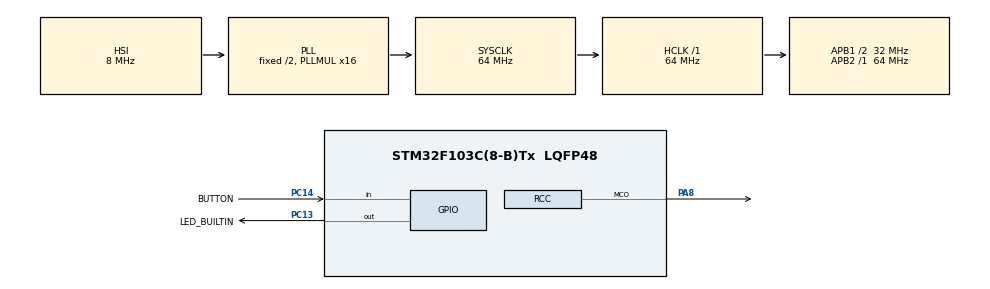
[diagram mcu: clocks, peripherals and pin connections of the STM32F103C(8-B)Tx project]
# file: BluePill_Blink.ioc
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Mcu.Family=STM32F1
PC13-TAMPER-RTC.Signal=GPIO_Output
RCC.APB1CLKDivider=RCC_HCLK_DIV2
PC14-OSC32_IN.Signal=GPIO_Input
RCC.SYSCLKSource=RCC_SYSCLKSOURCE_PLLCLK
ProjectManager.StackSize=0x400
PA13.Signal=SYS_JTMS-SWDIO
ProjectManager.TargetToolchain=STM32CubeIDE
RCC.HCLKFreq_Value=64000000
RCC.APB2TimFreq_Value=64000000
RCC.USBFreq_Value=64000000
RCC.AHBFreq_Value=64000000
board=custom
RCC.PLLMUL=RCC_PLL_MUL16
PC13-TAMPER-RTC.GPIO_Label=LED_BUILTIN
RCC.APB2Freq_Value=64000000
PA14.Mode=Serial_Wire
RCC.RCC_MCOSource=RCC_MCO1SOURCE_PLLCLK
PA8.Signal=RCC_MCO
PA13.Mode=Serial_Wire
Mcu.Name=STM32F103C(8-B)Tx
RCC.SYSCLKFreq_VALUE=64000000
Mcu.Package=LQFP48
PA14.Signal=SYS_JTCK-SWCLK
ProjectManager.HeapSize=0x200
NVIC.PriorityGroup=NVIC_PRIORITYGROUP_4
RCC.APB1TimFreq_Value=64000000
PA8.Mode=Clock-out
PC14-OSC32_IN.GPIO_Label=BUTTON
RCC.APB1Freq_Value=32000000

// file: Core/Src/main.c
/* USER CODE BEGIN Header */
/**
  ******************************************************************************
  * @file           : main.c
  * @brief          : Main program body
  ******************************************************************************
  * @attention
  *
  * <h2><center>&copy; Copyright (c) 2021 STMicroelectronics.
  * All rights reserved.</center></h2>
  *
  * This software component is licensed by ST under BSD 3-Clause license,
  * the "License"; You may not use this file except in compliance with the
  * License. You may obtain a copy of the License at:
  *                        opensource.org/licenses/BSD-3-Clause
  *
  ******************************************************************************
  */
/* USER CODE END Header */
#include "main.h"

void SystemClock_Config(void);
static void MX_GPIO_Init(void);

/* USER CODE BEGIN 0 */
uint8_t button_state = 0;
/* USER CODE END 0 */

int main(void)
{

  /* MCU Configuration--------------------------------------------------------*/

  /* Reset of all peripherals, Initializes the Flash interface and the Systick. */
  HAL_Init();

  /* Configure the system clock */
  SystemClock_Config();

  /* Initialize all configured peripherals */
  MX_GPIO_Init();

  /* Infinite loop */
  /* USER CODE BEGIN WHILE */
  while (1)
  {
	  button_state = HAL_GPIO_ReadPin(BUTTON_GPIO_Port, BUTTON_Pin);
	  HAL_GPIO_WritePin(LED_BUILTIN_GPIO_Port, LED_BUILTIN_Pin, button_state);
    /* USER CODE END WHILE */

  }
}

void SystemClock_Config(void)
{
  RCC_OscInitTypeDef RCC_OscInitStruct = {0};
  RCC_ClkInitTypeDef RCC_ClkInitStruct = {0};

  /** Initializes the RCC Oscillators according to the specified parameters
  * in the RCC_OscInitTypeDef structure.
  */
  RCC_OscInitStruct.OscillatorType = RCC_OSCILLATORTYPE_HSI;
  RCC_OscInitStruct.HSIState = RCC_HSI_ON;
  RCC_OscInitStruct.HSICalibrationValue = RCC_HSICALIBRATION_DEFAULT;
  RCC_OscInitStruct.PLL.PLLState = RCC_PLL_ON;
  RCC_OscInitStruct.PLL.PLLSource = RCC_PLLSOURCE_HSI_DIV2;
  RCC_OscInitStruct.PLL.PLLMUL = RCC_PLL_MUL16;
  if (HAL_RCC_OscConfig(&RCC_OscInitStruct) != HAL_OK)
  {
    Error_Handler();
  }
  /** Initializes the CPU, AHB and APB buses clocks
  */
  RCC_ClkInitStruct.ClockType = RCC_CLOCKTYPE_HCLK|RCC_CLOCKTYPE_SYSCLK
                              |RCC_CLOCKTYPE_PCLK1|RCC_CLOCKTYPE_PCLK2;
  RCC_ClkInitStruct.SYSCLKSource = RCC_SYSCLKSOURCE_PLLCLK;
  RCC_ClkInitStruct.AHBCLKDivider = RCC_SYSCLK_DIV1;
  RCC_ClkInitStruct.APB1CLKDivider = RCC_HCLK_DIV2;
  RCC_ClkInitStruct.APB2CLKDivider = RCC_HCLK_DIV1;

  if (HAL_RCC_ClockConfig(&RCC_ClkInitStruct, FLASH_LATENCY_2) != HAL_OK)
  {
    Error_Handler();
  }
  HAL_RCC_MCOConfig(RCC_MCO, RCC_MCO1SOURCE_PLLCLK, RCC_MCODIV_1);
}

static void MX_GPIO_Init(void)
{
  GPIO_InitTypeDef GPIO_InitStruct = {0};

  /* GPIO Ports Clock Enable */
  __HAL_RCC_GPIOC_CLK_ENABLE();
  __HAL_RCC_GPIOA_CLK_ENABLE();

  /*Configure GPIO pin Output Level */
  HAL_GPIO_WritePin(LED_BUILTIN_GPIO_Port, LED_BUILTIN_Pin, GPIO_PIN_RESET);

  /*Configure GPIO pin : LED_BUILTIN_Pin */
  GPIO_InitStruct.Pin = LED_BUILTIN_Pin;
  GPIO_InitStruct.Mode = GPIO_MODE_OUTPUT_PP;
  GPIO_InitStruct.Pull = GPIO_NOPULL;
  GPIO_InitStruct.Speed = GPIO_SPEED_FREQ_LOW;
  HAL_GPIO_Init(LED_BUILTIN_GPIO_Port, &GPIO_InitStruct);

  /*Configure GPIO pin : BUTTON_Pin */
  GPIO_InitStruct.Pin = BUTTON_Pin;
  GPIO_InitStruct.Mode = GPIO_MODE_INPUT;
  GPIO_InitStruct.Pull = GPIO_NOPULL;
  HAL_GPIO_Init(BUTTON_GPIO_Port, &GPIO_InitStruct);

  /*Configure GPIO pin : PA8 */
  GPIO_InitStruct.Pin = GPIO_PIN_8;
  GPIO_InitStruct.Mode = GPIO_MODE_AF_PP;
  GPIO_InitStruct.Speed = GPIO_SPEED_FREQ_LOW;
  HAL_GPIO_Init(GPIOA, &GPIO_InitStruct);

}

void Error_Handler(void)
{
  __disable_irq();
  while (1)
  {
  }
}

/************************ (C) COPYRIGHT STMicroelectronics *****END OF FILE****/
